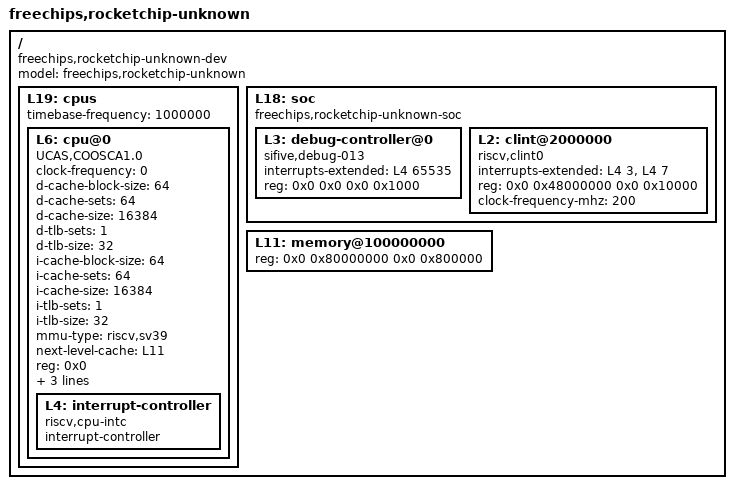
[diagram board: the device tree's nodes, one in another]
/dts-v1/;

/ {
	#address-cells = <2>;
	#size-cells = <2>;
	compatible = "freechips,rocketchip-unknown-dev";
	model = "freechips,rocketchip-unknown";
	L19: cpus {
		#address-cells = <1>;
		#size-cells = <0>;
		timebase-frequency = <1000000>;
		L6: cpu@0 {
			clock-frequency = <0>;
			compatible = "UCAS,COOSCA1.0", "riscv";
			d-cache-block-size = <64>;
			d-cache-sets = <64>;
			d-cache-size = <16384>;
			d-tlb-sets = <1>;
			d-tlb-size = <32>;
			device_type = "cpu";
			i-cache-block-size = <64>;
			i-cache-sets = <64>;
			i-cache-size = <16384>;
			i-tlb-sets = <1>;
			i-tlb-size = <32>;
			mmu-type = "riscv,sv39";
			next-level-cache = <&L11>;
			reg = <0x0>;
			riscv,isa = "rv64imac";
			status = "okay";
			timebase-frequency = <1000000>;
			tlb-split;
			L4: interrupt-controller {
				#interrupt-cells = <1>;
				compatible = "riscv,cpu-intc";
				interrupt-controller;
			};
		};
	};
	L18: soc {
		#address-cells = <2>;
		#size-cells = <2>;
		compatible = "freechips,rocketchip-unknown-soc", "simple-bus";
		ranges;
		L3: debug-controller@0 {
			compatible = "sifive,debug-013", "riscv,debug-013";
			interrupts-extended = <&L4 65535>;
			reg = <0x0 0x0 0x0 0x1000>;
			reg-names = "control";
		};
		L2: clint@2000000 {
			compatible = "riscv,clint0";
			interrupts-extended = <&L4 3 &L4 7>;
			reg = <0x0 0x48000000 0x0 0x10000>;
			clock-frequency-mhz = <200>;
			reg-names = "control";
		};
	};
	L11: memory@100000000 {
		device_type = "memory";
		reg = <0x0 0x80000000 0x0 0x800000>;
	};
};
